# HSM_DCC register map
Vendor: Texas Instruments
Peripheral module from a debugger description file (folder awr2544).
Registers are 32-bit, access per field, no defined reset value unless marked. A register's access mark holds for its fields unless they carry their own. Offsets are as the file gives them; lines under a group give offsets from that group; [hi:lo] are bit positions; {n}, {i} and the like mark numbered series; 'fields as' and 'values as' point back to an identical list; <NAME> marks a mode.

## HSM_DCC
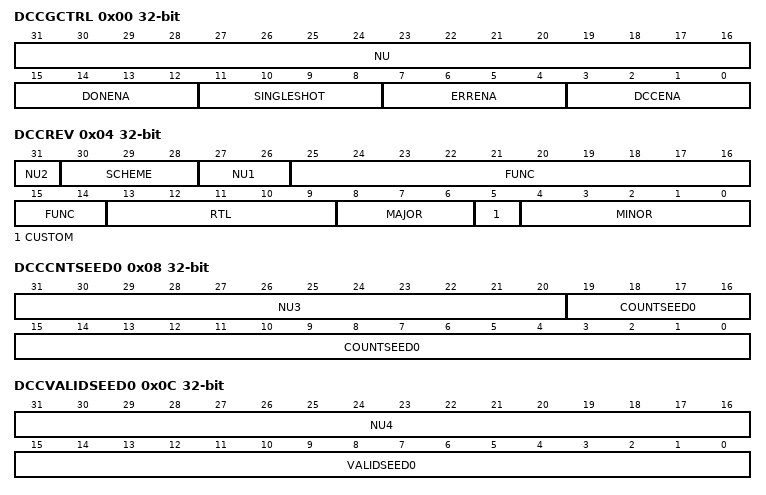
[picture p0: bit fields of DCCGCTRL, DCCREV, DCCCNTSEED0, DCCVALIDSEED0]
0x00 DCCGCTRL — Starts / stops the counters clears the error signal
  [31:16] NU ro — Reserved
  [15:12] DONENA rw — The DONEENA bit enables/disables the done signal. 0101 = disabled & 1010 = enabled
  [11:8] SINGLESHOT rw — Single/Continuous checking mode. 0101 = Continuous & 1010 = Single
  [7:4] ERRENA rw — The ERRENA bit enables/disables the error signal. 0101 = disabled & 1010 = enabled
  [3:0] DCCENA rw — The DCCENA bit starts and stops the operation of the dcc 0101 = disabled & 1010 = enabled
0x04 DCCREV ro — Module version
  [31] NU2 — Reserved
  [30:28] SCHEME — SCHEME. - (RO )
  [27:26] NU1 — Reserved
  [25:14] FUNC — Functional release number - (RO )
  [13:9] RTL — Design Release Number - (RO )
  [8:6] MAJOR — Major Revision Number - (RO )
  [5] CUSTOM — Indicates a special version of the module. May not be supported by standard software - (RO )
  [4:0] MINOR — Minor revision number. - (RO )
0x08 DCCCNTSEED0 — Seed value for the counter attached to clock source 0
  [31:20] NU3 ro — Reserved
  [19:0] COUNTSEED0 rw — The seed value for Counter 0. The seed value that gets loaded into counter 0 (clock source 0)
0x0C DCCVALIDSEED0 — Seed value for the timeout counter attached to clock source 0
  [31:16] NU4 ro — Reserved
  [15:0] VALIDSEED0 rw — The seed value for Valid Duration Counter 0.The seed value that gets loaded into the valid duration counter for clock source 0
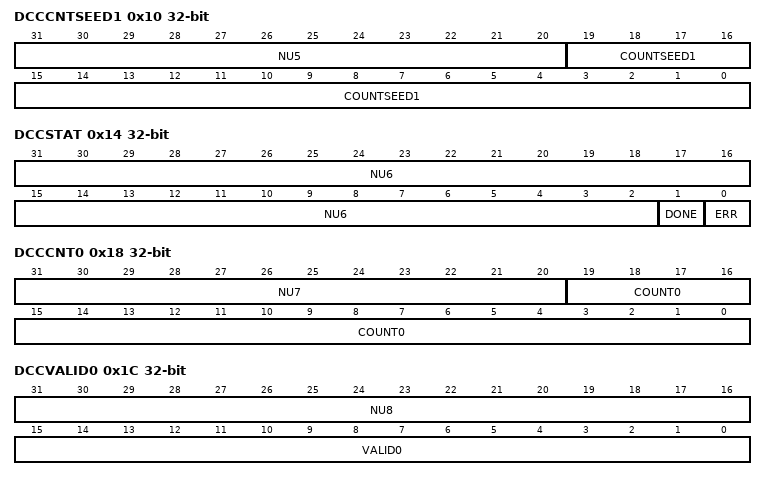
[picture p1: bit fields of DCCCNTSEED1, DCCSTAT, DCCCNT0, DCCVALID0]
0x10 DCCCNTSEED1 — Seed value for the counter attached to clock source 1
  [31:20] NU5 ro — Reserved
  [19:0] COUNTSEED1 rw — The seed value for Counter 1. The seed value that gets loaded into counter 1 (clock source 1
0x14 DCCSTAT — Contains the error & done flag bit
  [31:2] NU6 ro — Reserved
  [1] DONE rw — Indicates whether or not an done has occured. Writing a 1 to this bit clears the flag.
  [0] ERR rw — Indicates whether or not an error has occured. Writing a 1 to this bit clears the flag.
0x18 DCCCNT0 ro — Value of the counter attached to clock source 0
  [31:20] NU7 — Reserved
  [19:0] COUNT0 — This field contains the current value of counter 0. - (RO )
0x1C DCCVALID0 ro — Value of the valid counter attached to clock source 0
  [31:16] NU8 — Reserved
  [15:0] VALID0 — This field contains the current value of valid counter 0. - (RO )
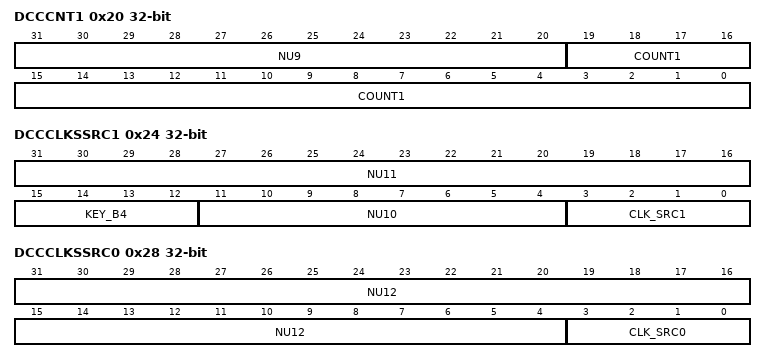
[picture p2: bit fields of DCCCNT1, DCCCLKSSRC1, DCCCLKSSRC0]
0x20 DCCCNT1 ro — Value of the counter attached to clock source 1
  [31:20] NU9 — Reserved
  [19:0] COUNT1 — This field contains the current value of counter 1. - (RO )
0x24 DCCCLKSSRC1 — Clock source1 selection control
  [31:16] NU11 ro — Reserved
  [15:12] KEY_B4 rw — Key Programing (1010 is the KEY Value)
  [11:4] NU10 ro — Reserved
  [3:0] CLK_SRC1 rw — Clock source selection for Source 0 DCC-A Clock source-0 selection Program value and its respective clock selected 0x0 - REF_CLK 0x1 - CPU_CLK 0x2 - RC_CLK 0x3 - RC_CLK 0x4 - RC_CLK 0x5 - RC_CLK 0x6 - RC_CLK 0x7 - RC_CLK DCC-B Clock source-0 selection Program value and its respective clock selected 0x0 - VCLK 0x1 - DSS_CLK 0x2 - BSS_CLK 0x3 - QSPI_CLK 0x4 - FDCAN_CLK 0x5 - REF_CLK 0x6 - CPU_CLK 0x7 - RC_CLK
0x28 DCCCLKSSRC0 — Clock source0 selection control
  [31:4] NU12 ro — Reserved
  [3:0] CLK_SRC0 rw — Clock source selection for Source 0 DCC-A Clock source-0 selection Program value and its respective clock selected 0 - REF_CLK A - PLL_600 5 - PLL_240 DCC-B Clock source-0 selection Program value and its respective clock selected 0 - PLL_600 A - VCLK 5 - CPU_CLK
